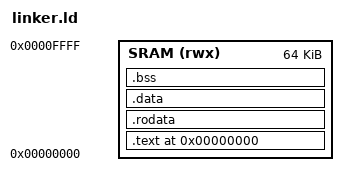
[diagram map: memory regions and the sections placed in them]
ENTRY(_start)

MEMORY
{
    SRAM (rwx) : ORIGIN = 0x00000000, LENGTH = 64K
}

SECTIONS
{
    . = ORIGIN(SRAM);
    
    .text : {
        *(.text.boot)
        *(.text*)
    } > SRAM

    .rodata : {
        *(.rodata*)
    } > SRAM

    .data : {
        *(.data*)
    } > SRAM

    .bss : {
        __bss_start = .;
        *(.bss*)
        *(COMMON)
        __bss_end = .;
    } > SRAM
}
